# G32F031 register map
File version: 1.0
CPU: CM0PLUS r0p1, little endian, no MPU, no FPU, 2 interrupt priority bits
Registers are 32-bit, read-write, reset 0x0 unless marked. A register's access mark holds for its fields unless they carry their own. Offsets are from the block's base; lines under a group give offsets from that group; [hi:lo] are bit positions; {n}, {i} and the like mark numbered series; 'fields as' and 'values as' point back to an identical list; <NAME> marks a mode.

## Memory map
0x40000000 PMU size 0x400 — Power Manage Unit
0x40000400 SCU size 0x400 — System Control Unit
0x40000800 EINT size 0x400 — External interrupt/event controller
0x40000C00 ATMR size 0x400 — Advance timer
0x40001000 GTMR size 0x400 — General purpose timer
0x40001800 BTMR0 size 0x400 — Base timer
0x40001C00 BTMR1 size 0x400 — Base timer
0x40002000 LPTMR size 0x400 — Low-power timer
0x40002800 IWDT size 0x400 — Independent watchdog
0x40002C00 WWDT size 0x400 — Window watchdog
0x40003000 SPI size 0x400 — Serial peripheral interface
0x40003800 USART size 0x400 — Universal asynchronous receiver transmitter
0x40003C00 UART size 0x400 — Universal asynchronous receiver transmitter
0x40004400 I2C size 0x400 — Inter-Integrated Circuit
0x40005400 ADC size 0x400 — Analog-to-digital converter
0x40005800 OPA size 0x400
0x40005C00 COMP0 size 0x400 — Comparator
0x40006000 COMP1 size 0x400 — Comparator
0x40020000 DMA size 0x400 — DMA controller
0x40020400 RCC size 0x400 — Reset and clock control
0x40020800 FLASH size 0x400 — Flash memory controller
0x40020C00 CRC size 0x400 — Cryptographic processor
0x40021000 DIV size 0x400
0x48000000 GPIOA size 0x400 — General-purpose I/Os
0x48000400 GPIOB size 0x400 — General-purpose I/Os

## Interrupts
0 WWDT — Window Watchdog global interrupt
1 PVD (PMU, RCC) — PVD global interrupt
3 FLASH — FLASH global interrupt
4 RCC — RCC global interrupt
5 EINT0_1 (EINT) — EINT Line 0 to 1 global interrupt
6 EINT2_3 (EINT) — EINT Line 2 to 3 global interrupt
7 EINT4_15 (EINT) — EINT Line 4 to 15 global interrupts
9 DMA_CH0 (DMA) — DMA_CH0 global interrupt
10 DMA_CH1 (DMA) — DMA_CH1 global interrupts
12 ADC — ADC global interrupt
13 ATMR_BRK_UP_TRG_COM (ATMR) — ATMR_BRK_UP_TRG_COM global interrupt
14 ATMR_CC (ATMR) — ATMR_CC global interrupt
15 GTMR — GTMR interrupt
17 BTMR0 — BTMR0 global interrupt
18 BTMR1 — BTMR1 global interrupt
19 LPTMR — LPTMR global interrupt
21 COMP0 — COMP0 global interrupt
22 COMP1_2_3 (COMP1) — COMP1/2/3 global interrupt
23 I2C1 (I2C) — I2C1 global interrupt
25 SPI1 (SPI) — SPI1 global interrupt
27 USART0 (USART) — USART0 global interrupt
28 UART0 (UART) — UART0 global interrupt

## BTMR0 — Base timer
Base 0x40001800
Same registers: BTMR1 0x40001C00
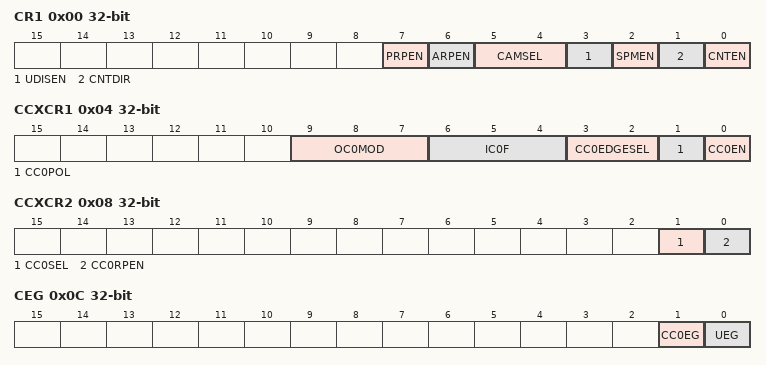
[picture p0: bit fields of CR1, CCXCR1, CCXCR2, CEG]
0x00 CR1 — control register 1
  [7] PRPEN — PSC preload enable
  [6] ARPEN — Auto-reload Preload Enable
  [5:4] CAMSEL — Choose center alignment mode
  [3] UDISEN — Update Disable
  [2] SPMEN — Single Pulse Mode Enable
  [1] CNTDIR — Counter Direction
  [0] CNTEN — BTMR enable
0x04 CCXCR1 — channel control register 1
  [9:7] OC0MOD — Output Compare Channel0 Mode Configure
  [6:4] IC0F — Input filter coefficients (based on timer clock)
  [3:2] CC0EDGESEL — When in input mode: capture the active edge
  [1] CC0POL — Capture/Compare Channel1 Output Polarity Configure
  [0] CC0EN — Capture/compare enable
0x08 CCXCR2 — channel control register 2
  [1] CC0SEL — Channel 0 Input/Output Selection
  [0] CC0RPEN — CCR0 register auto-reload buffer enable
0x0C CEG wo — event generation register
  [1] CC0EG — Capture/compare 0 generation
  [0] UEG — Update generation
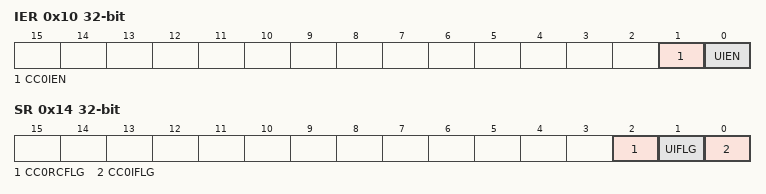
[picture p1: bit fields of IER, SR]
0x10 IER — interrupt enable register
  [1] CC0IEN — Capture/compare 0 interrupt enable
  [0] UIEN — Update interrupt enable
0x14 SR — status register
  [2] CC0RCFLG — Captuer/Compare Channel0 Repetition Capture Flag
  [1] UIFLG — Update interrupt flag
  [0] CC0IFLG — Capture/compare 0 interrupt flag
0x18 CNT — counter
  [15:0] CNT — Counter Value
0x1C PSC — prescaler
  [15:0] PSC — Prescaler value
0x20 AUTORLD reset 0xFFFF — auto-reload register
  [15:0] AUTORLD — Auto Reload Value
0x24 CC0 — capture/compare register 0
  [15:0] CC0 — Capture/Compare 0 value
